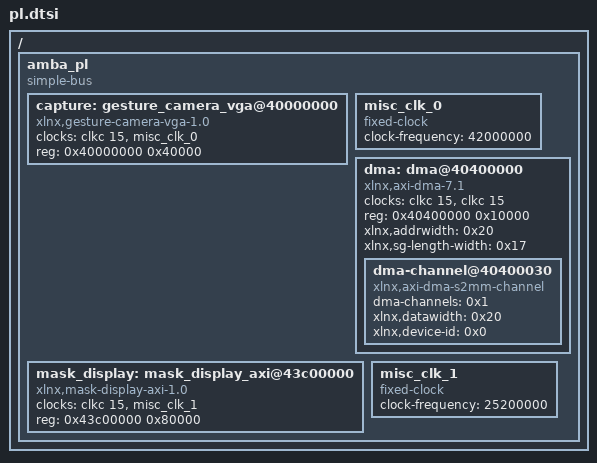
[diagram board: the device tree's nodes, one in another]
/*
 * CAUTION: This file is automatically generated by Xilinx.
 * Version:  
 * Today is: Mon Nov  2 12:04:15 2026
 */


/ {
	amba_pl: amba_pl {
		#address-cells = <1>;
		#size-cells = <1>;
		compatible = "simple-bus";
		ranges ;
		capture: gesture_camera_vga@40000000 {
			clock-names = "s_axi_aclk", "cam_pclk";
			clocks = <&clkc 15>, <&misc_clk_0>;
			compatible = "xlnx,gesture-camera-vga-1.0";
			reg = <0x40000000 0x40000>;
		};
		misc_clk_0: misc_clk_0 {
			#clock-cells = <0>;
			clock-frequency = <42000000>;
			compatible = "fixed-clock";
		};
		dma: dma@40400000 {
			#dma-cells = <1>;
			clock-names = "s_axi_lite_aclk", "m_axi_s2mm_aclk";
			clocks = <&clkc 15>, <&clkc 15>;
			compatible = "xlnx,axi-dma-7.1", "xlnx,axi-dma-1.00.a";
			reg = <0x40400000 0x10000>;
			xlnx,addrwidth = <0x20>;
			xlnx,sg-length-width = <0x17>;
			dma-channel@40400030 {
				compatible = "xlnx,axi-dma-s2mm-channel";
				dma-channels = <0x1>;
				xlnx,datawidth = <0x20>;
				xlnx,device-id = <0x0>;
			};
		};
		mask_display: mask_display_axi@43c00000 {
			clock-names = "s_axi_aclk", "pixel_clk";
			clocks = <&clkc 15>, <&misc_clk_1>;
			compatible = "xlnx,mask-display-axi-1.0";
			reg = <0x43c00000 0x80000>;
		};
		misc_clk_1: misc_clk_1 {
			#clock-cells = <0>;
			clock-frequency = <25200000>;
			compatible = "fixed-clock";
		};
	};
};
